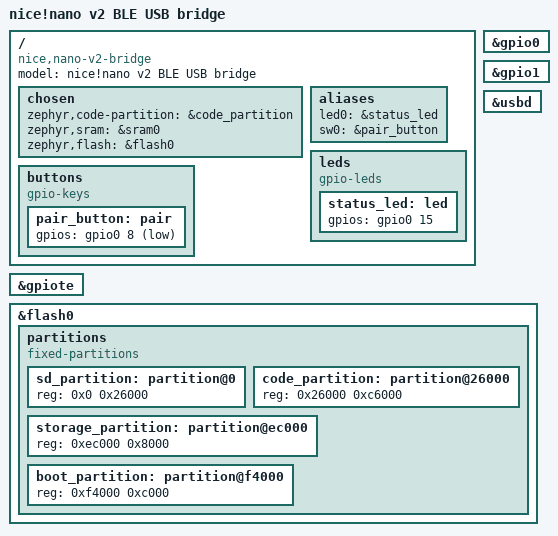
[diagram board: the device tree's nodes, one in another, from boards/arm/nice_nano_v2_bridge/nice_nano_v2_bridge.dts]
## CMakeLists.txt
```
cmake_minimum_required(VERSION 3.20.0)
list(APPEND BOARD_ROOT ${CMAKE_CURRENT_SOURCE_DIR})
find_package(Zephyr REQUIRED HINTS $ENV{ZEPHYR_BASE})
project(nicenano_ble_usb)
target_sources(app PRIVATE src/main.c src/hid_map.c)
```

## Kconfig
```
mainmenu "nice!nano BLE to USB HID bridge"
source "Kconfig.zephyr"

config BRIDGE_PEER_NAME
    string "Exact advertising name allowed during first pairing (empty allows any HID)"
    default "wenwan"
```

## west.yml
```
manifest:
  remotes:
    - name: zmkfirmware
      url-base: https://github.com/zmkfirmware
  projects:
    - name: zephyr
      remote: zmkfirmware
      revision: dacab4875df72109b96cc8977547a0dc04875bcd
      import:
        name-allowlist:
          - cmsis
          - hal_nordic
          - tinycrypt
          - segger
          - picolibc
  self:
    path: nicenano-ble-usb
```

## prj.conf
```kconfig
CONFIG_BT=y
CONFIG_BT_CENTRAL=y
CONFIG_BT_OBSERVER=y
CONFIG_BT_GATT_CLIENT=y
CONFIG_BT_SMP=y
CONFIG_BT_BONDABLE=y
CONFIG_BT_SETTINGS=y
CONFIG_BT_PRIVACY=y
CONFIG_BT_MAX_CONN=1
CONFIG_BT_MAX_PAIRED=1
CONFIG_BT_DEVICE_NAME="nice!nano HID Bridge"
CONFIG_BT_BUF_ACL_RX_SIZE=251
CONFIG_BT_BUF_ACL_TX_SIZE=251
CONFIG_BT_L2CAP_TX_MTU=247
CONFIG_SETTINGS=y
CONFIG_NVS=y
CONFIG_SETTINGS_NVS=y
CONFIG_FLASH=y
CONFIG_FLASH_PAGE_LAYOUT=y
CONFIG_FLASH_MAP=y
CONFIG_MPU_ALLOW_FLASH_WRITE=y
CONFIG_USB_DEVICE_STACK=y
CONFIG_USB_DEVICE_HID=y
CONFIG_USB_DEVICE_INITIALIZE_AT_BOOT=n
CONFIG_USB_DEVICE_PRODUCT="nice!nano BLE HID Bridge (experimental)"
CONFIG_USB_DEVICE_MANUFACTURER="Local development"
# Zephyr development VID/PID; obtain your own identifiers for distribution.
CONFIG_USB_DEVICE_VID=0x2FE3
CONFIG_USB_DEVICE_PID=0x0100
CONFIG_USB_SELF_POWERED=n
CONFIG_USB_DEVICE_SN="NNBLEUSB0001"
CONFIG_HID_INTERRUPT_EP_MPS=64
CONFIG_USB_HID_POLL_INTERVAL_MS=1
CONFIG_USB_HID_REPORTS=256
CONFIG_ENABLE_HID_INT_OUT_EP=y
CONFIG_USB_REQUEST_BUFFER_SIZE=2048
CONFIG_GPIO=y
CONFIG_REBOOT=y
CONFIG_MAIN_STACK_SIZE=6144
CONFIG_SYSTEM_WORKQUEUE_STACK_SIZE=2048
CONFIG_BT_RX_STACK_SIZE=3072
CONFIG_HEAP_MEM_POOL_SIZE=8192
CONFIG_LOG=y
CONFIG_USE_SEGGER_RTT=y
CONFIG_LOG_BACKEND_RTT=y
CONFIG_LOG_BACKEND_UART=n
CONFIG_CONSOLE=n
CONFIG_UART_CONSOLE=n
CONFIG_SERIAL=n
```

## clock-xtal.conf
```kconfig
# Controlled comparison against the LF clock used by the nice_nano_v2 ZMK build.
CONFIG_CLOCK_CONTROL_NRF_K32SRC_RC=n
CONFIG_CLOCK_CONTROL_NRF_K32SRC_RC_CALIBRATION=n
CONFIG_CLOCK_CONTROL_NRF_K32SRC_XTAL=y
CONFIG_CLOCK_CONTROL_NRF_K32SRC_500PPM=n
CONFIG_CLOCK_CONTROL_NRF_K32SRC_50PPM=y
```

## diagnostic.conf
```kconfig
# Compatibility diagnostics: no external 32.768 kHz crystal required.
CONFIG_CLOCK_CONTROL_NRF_K32SRC_RC=y
CONFIG_CLOCK_CONTROL_NRF_K32SRC_RC_CALIBRATION=y
CONFIG_CLOCK_CONTROL_NRF_K32SRC_500PPM=y
# USB HID remains present; a second USB interface exposes diagnostic logs.
CONFIG_USB_COMPOSITE_DEVICE=y
CONFIG_USB_CDC_ACM=y
CONFIG_SERIAL=y
CONFIG_CONSOLE=y
CONFIG_UART_CONSOLE=y
CONFIG_UART_LINE_CTRL=y
CONFIG_LOG_BACKEND_UART=y
CONFIG_USB_DEVICE_PRODUCT="nice!nano HID Bridge v8.1 Web Console"
CONFIG_ASSERT=y
CONFIG_HW_STACK_PROTECTION=y
CONFIG_USB_DEVICE_PID=0x0101
CONFIG_USB_NRFX_WORK_QUEUE_STACK_SIZE=2048

# Preserve complete control responses during device-list bursts.
CONFIG_LOG_BUFFER_SIZE=8192
CONFIG_USB_CDC_ACM_RINGBUF_SIZE=4096
```

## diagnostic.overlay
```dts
/ {
    chosen { zephyr,console = &bridge_console; };
};
&usbd {
    bridge_console: cdc_acm_uart0 { compatible = "zephyr,cdc-acm-uart"; };
};
```

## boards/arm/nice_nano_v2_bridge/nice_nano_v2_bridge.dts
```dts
/dts-v1/;
#include <nordic/nrf52840_qiaa.dtsi>
#include <zephyr/dt-bindings/gpio/gpio.h>

/ {
    model = "nice!nano v2 BLE USB bridge";
    compatible = "nice,nano-v2-bridge";
    chosen {
        zephyr,code-partition = &code_partition;
        zephyr,sram = &sram0;
        zephyr,flash = &flash0;
    };
    aliases { led0 = &status_led; sw0 = &pair_button; };
    leds {
        compatible = "gpio-leds";
        status_led: led { gpios = <&gpio0 15 GPIO_ACTIVE_HIGH>; };
    };
    buttons {
        compatible = "gpio-keys";
        /* Optional button: nice!nano D0/P0.08 to GND; never use RESET. */
        pair_button: pair { gpios = <&gpio0 8 (GPIO_PULL_UP | GPIO_ACTIVE_LOW)>; };
    };
};
&gpio0 { status = "okay"; };
&gpio1 { status = "okay"; };
&gpiote { status = "okay"; };
&usbd { status = "okay"; };
&flash0 {
    partitions {
        compatible = "fixed-partitions";
        #address-cells = <1>;
        #size-cells = <1>;
        sd_partition: partition@0 { reg = <0x0 0x26000>; };
        code_partition: partition@26000 { reg = <0x26000 0xc6000>; };
        storage_partition: partition@ec000 { reg = <0xec000 0x8000>; };
        boot_partition: partition@f4000 { reg = <0xf4000 0xc000>; };
    };
};
```

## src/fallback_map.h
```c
/* Fallback USB descriptor from the verified wenwan ZMK build. */
#pragma once
static const unsigned char fallback_map[] = {
    0x05,0x01,0x09,0x06,0xa1,0x01,0x85,0x01,0x05,0x07,0x19,0xe0,0x29,0xe7,0x15,0x00,
    0x25,0x01,0x75,0x01,0x95,0x08,0x81,0x02,0x05,0x07,0x75,0x08,0x95,0x01,0x81,0x03,
    0x05,0x07,0x15,0x00,0x26,0xff,0x00,0x19,0x00,0x29,0xff,0x75,0x08,0x95,0x06,0x81,
    0x00,0xc0,0x05,0x0c,0x09,0x01,0xa1,0x01,0x85,0x02,0x05,0x0c,0x15,0x00,0x26,0xff,
    0x0f,0x19,0x00,0x2a,0xff,0x0f,0x75,0x10,0x95,0x06,0x81,0x00,0xc0,0x05,0x01,0x09,
    0x02,0xa1,0x01,0x85,0x03,0x09,0x01,0xa1,0x00,0x05,0x09,0x19,0x01,0x29,0x05,0x15,
    0x00,0x25,0x01,0x75,0x01,0x95,0x05,0x81,0x02,0x75,0x03,0x95,0x01,0x81,0x03,0x05,
    0x01,0x09,0x30,0x09,0x31,0x16,0x00,0x80,0x26,0xff,0x7f,0x75,0x10,0x95,0x02,0x81,
    0x06,0xa1,0x02,0x09,0x38,0x16,0x00,0x80,0x26,0xff,0x7f,0x35,0x00,0x45,0x00,0x75,
    0x10,0x95,0x01,0x81,0x06,0xc0,0xa1,0x02,0x05,0x0c,0x0a,0x38,0x02,0x16,0x00,0x80,
    0x26,0xff,0x7f,0x35,0x00,0x45,0x00,0x75,0x10,0x95,0x01,0x81,0x06,0xc0,0xc0,0xc0,
};
```

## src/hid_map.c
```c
#include "hid_map.h"
#include <errno.h>
#include <string.h>

struct globals { uint32_t size, count; uint8_t id; };

int hid_map_parse(const uint8_t *map, size_t len, struct hid_map_info *info)
{
    struct globals g = {0}, stack[8];
    unsigned depth = 0;
    uint32_t bits[2][256] = {{0}};
    bool has_input = false;
    memset(info, 0, sizeof(*info));
    if (!len || len > BRIDGE_MAP_MAX) return -EINVAL;
    for (size_t pos = 0; pos < len;) {
        uint8_t prefix = map[pos++];
        if (prefix == 0xfe) return -ENOTSUP; /* HID long items are not handled. */
        unsigned n = prefix & 3;
        if (n == 3) n = 4;
        if (pos + n > len) return -EINVAL;
        uint32_t value = 0;
        for (unsigned j = 0; j < n; j++) value |= (uint32_t)map[pos+j] << (8*j);
        pos += n;
        unsigned type = (prefix >> 2) & 3, tag = prefix >> 4;
        if (type == 1) {
            switch (tag) {
            case 7: g.size = value; break;
            case 8:
                if (!value || value > 255) return -EINVAL;
                g.id = value; info->uses_ids = true; break;
            case 9: g.count = value; break;
            case 10:
                if (depth == 8) return -E2BIG;
                stack[depth++] = g; break;
            case 11:
                if (!depth) return -EINVAL;
                g = stack[--depth]; break;
            }
        } else if (type == 0 && (tag == 8 || tag == 9)) {
            unsigned k = tag == 8 ? 0 : 1;
            if (g.size > 512 || g.count > 512 || g.size * g.count > 512)
                return -EMSGSIZE;
            bits[k][g.id] += g.size * g.count;
            if (bits[k][g.id] > 512) return -EMSGSIZE;
            if (k == 0) has_input = true;
        }
    }
    if (depth || !has_input || (info->uses_ids && (bits[0][0] || bits[1][0])))
        return -EINVAL;
    for (unsigned id = 0; id < 256; id++) {
        unsigned in = (bits[0][id]+7)/8, out = (bits[1][id]+7)/8;
        if (in + info->uses_ids > BRIDGE_PACKET_MAX ||
            out + info->uses_ids > BRIDGE_PACKET_MAX) return -EMSGSIZE;
        info->input_len[id] = in;
        info->output_len[id] = out;
    }
    return 0;
}

int hid_packet(const struct hid_map_info *info, uint8_t id,
               const uint8_t *data, size_t len, uint8_t *out)
{
    if (!info->input_len[id] || len != info->input_len[id] ||
        (!info->uses_ids && id != 0)) return -EINVAL;
    unsigned offset = info->uses_ids ? 1 : 0;
    if (offset) out[0] = id;
    memcpy(out+offset, data, len);
    return len+offset;
}
```

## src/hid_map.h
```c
#pragma once
#include <stdbool.h>
#include <stddef.h>
#include <stdint.h>

#define BRIDGE_PACKET_MAX 64
#define BRIDGE_MAP_MAX 1536

struct hid_map_info {
    bool uses_ids;
    uint8_t input_len[256];  /* Payload length, without report ID. */
    uint8_t output_len[256];
};
/* Reject malformed maps, unnumbered/numbered mixtures and oversized reports. */
int hid_map_parse(const uint8_t *map, size_t len, struct hid_map_info *info);
int hid_packet(const struct hid_map_info *info, uint8_t id,
               const uint8_t *data, size_t len, uint8_t *out);
```
